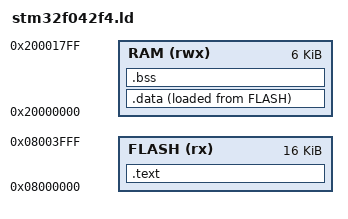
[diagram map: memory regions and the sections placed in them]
/* STM32F042F4P6: 16 KB flash at 0x08000000, 6 KB RAM at 0x20000000 */
MEMORY
{
  FLASH (rx) : ORIGIN = 0x08000000, LENGTH = 16K
  RAM  (rwx) : ORIGIN = 0x20000000, LENGTH = 6K
}
_estack = ORIGIN(RAM) + LENGTH(RAM);
ENTRY(Reset_Handler)
SECTIONS
{
  .text : { KEEP(*(.isr_vector)) *(.text*) *(.rodata*) . = ALIGN(4); _etext = .; } > FLASH
  _sidata = LOADADDR(.data);
  .data : { . = ALIGN(4); _sdata = .; *(.data*) . = ALIGN(4); _edata = .; } > RAM AT> FLASH
  .bss : { . = ALIGN(4); _sbss = .; *(.bss*) *(COMMON) . = ALIGN(4); _ebss = .; } > RAM
}
